# ATtiny13A register map
Vendor: Atmel; File version: 1.0
CPU: other r0p0, little endian, no MPU, no FPU, 4 interrupt priority bits
Registers are 8-bit, read-write, reset 0x0 unless marked. A register's access mark holds for its fields unless they carry their own. Offsets are from the block's base; lines under a group give offsets from that group; [hi:lo] are bit positions; {n}, {i} and the like mark numbered series; 'fields as' and 'values as' point back to an identical list; <NAME> marks a mode.

## Memory map
0x00000000 FUSE size 0x2 — Fuses
0x00000000 LOCKBIT size 0x1 — Lockbits
0x00000023 AC blocks up to offset 0x12 — Analog Comparator
0x00000023 ADC blocks up to offset 0x12 — Analog-to-Digital Converter
0x00000035 EXINT blocks up to offset 0x27 — External Interrupts
0x00000036 PORTB size 0x3 — I/O Port
0x0000003C EEPROM size 0x3
0x00000041 WDT size 0x1 — Watchdog Timer
0x00000045 CPU blocks up to offset 0x19 — CPU Registers
0x00000048 TC0 blocks up to offset 0x12 — Timer/Counter, 8-bit

## Interrupts
0 RESET (CPU) — External Reset, Power-on Reset and Watchdog Reset
1 INT0 (CPU) — External Interrupt 0
2 PCINT0 (CPU) — External Interrupt Request 0
3 TIM0_OVF (CPU) — Timer/Counter0 Overflow
4 EE_RDY (CPU) — EEPROM Ready
5 ANA_COMP (CPU) — Analog Comparator
6 TIM0_COMPA (CPU) — Timer/Counter Compare Match A
7 TIM0_COMPB (CPU) — Timer/Counter Compare Match B
8 WDT (CPU) — Watchdog Time-out
9 ADC (CPU) — ADC Conversion Complete

## AC — Analog Comparator
Base 0x00000023
0x00 ADCSRB — ADC Control and Status Register B
  [6] ACME — Analog Comparator Multiplexer Enable
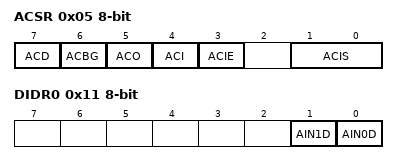
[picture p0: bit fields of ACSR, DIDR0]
0x05 ACSR — Analog Comparator Control And Status Register
  [7] ACD — Analog Comparator Disable
  [6] ACBG — Analog Comparator Bandgap Select
  [5] ACO — Analog Compare Output
  [4] ACI — Analog Comparator Interrupt Flag
  [3] ACIE — Analog Comparator Interrupt Enable
  [1:0] ACIS — Analog Comparator Interrupt Mode Select bits
    0=INTERRUPT_ON_TOGGLE; 2=INTERRUPT_ON_FALLING_EDGE; 3=INTERRUPT_ON_RISING_EDGE
0x11 DIDR0
  [1] AIN1D — AIN1 Digital Input Disable
  [0] AIN0D — AIN0 Digital Input Disable

## ADC — Analog-to-Digital Converter
Base 0x00000023
0x00 ADCSRB — ADC Control and Status Register B
  [2:0] ADTS — ADC Auto Trigger Sources
    0=FREE_RUNNING_MODE; 1=ANALOG_COMPARATOR; 2=EXTERNAL_INTERRUPT_REQUEST_0; 3=TIMER_COUNTER0_COMPARE_MATCH_A; 4=TIMER_COUNTER0_OVERFLOW; 5=TIMER_COUNTER1_COMPARE_MATCH_B; 6=TIMER_COUNTER1_OVERFLOW; 7=TIMER_COUNTER1_CAPTURE_EVENT
0x01 ADC 16-bit (reset mask 0xFF) — ADC Data Register Bytes
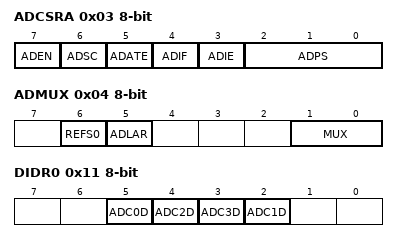
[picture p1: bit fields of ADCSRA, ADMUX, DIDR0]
0x03 ADCSRA — The ADC Control and Status register
  [7] ADEN — ADC Enable
  [6] ADSC — ADC Start Conversion
  [5] ADATE — ADC Auto Trigger Enable
  [4] ADIF — ADC Interrupt Flag
  [3] ADIE — ADC Interrupt Enable
  [2:0] ADPS — ADC Prescaler Select Bits
    1=2; 2=4; 3=8; 4=16; 5=32; 6=64; 7=128
0x04 ADMUX — The ADC multiplexer Selection Register
  [6] REFS0 — Reference Selection Bit 0
  [5] ADLAR — Left Adjust Result
  [1:0] MUX — Analog Channel and Gain Selection Bits
0x11 DIDR0 — Digital Input Disable Register 0
  [5] ADC0D — ADC0 Digital input Disable
  [4] ADC2D — ADC2 Digital input Disable
  [3] ADC3D — ADC3 Digital input Disable
  [2] ADC1D — ADC2 Digital input Disable

## CPU — CPU Registers
Base 0x00000045
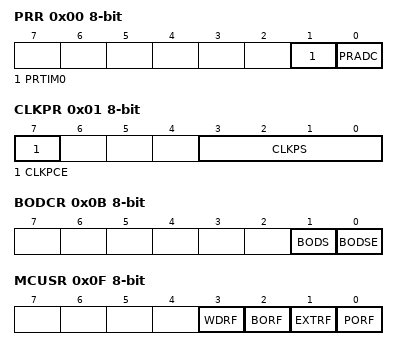
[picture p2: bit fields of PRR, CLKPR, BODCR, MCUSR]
0x00 PRR — Power Reduction Register
  [1] PRTIM0 — Power Reduction Timer/Counter0
  [0] PRADC — Power Reduction ADC
0x01 CLKPR — Clock Prescale Register
  [7] CLKPCE — Clock Prescaler Change Enable
  [3:0] CLKPS — Clock Prescaler Select Bits
    0=1; 1=2; 2=4; 3=8; 4=16; 5=32; 6=64; 7=128; 8=256
0x09 DWDR — Debug Wire Data Register
0x0B BODCR — BOD Control Register
  [1] BODS — BOD Power-Down in Power-Down Sleep
  [0] BODSE — BOD Power-Down Sleep Enable
0x0C OSCCAL — Oscillator Calibration Register
  [7:0] OSCCAL — Oscillator Calibration
0x0F MCUSR — MCU Status register
  [3] WDRF — Watchdog Reset Flag
  [2] BORF — Brown-out Reset Flag
  [1] EXTRF — External Reset Flag
  [0] PORF — Power-On Reset Flag
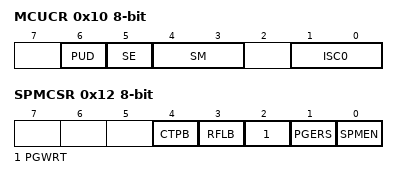
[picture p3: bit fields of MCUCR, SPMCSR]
0x10 MCUCR — MCU Control Register
  [6] PUD — Pull-up Disable
  [5] SE — Sleep Enable
  [4:3] SM — Sleep Mode Select Bits
    0=IDLE; 1=ADC (ADC Noise Reduction (If Available)); 2=PDOWN (Power Down)
  [1:0] ISC0 — Interrupt Sense Control 0 bits
    0=LOW_LEVEL_OF_INTX; 1=ANY_LOGICAL_CHANGE_IN_INTX; 2=FALLING_EDGE_OF_INTX; 3=RISING_EDGE_OF_INTX
0x12 SPMCSR — Store Program Memory Control and Status Register
  [4] CTPB — Clear Temporary Page Buffer
  [3] RFLB — Read Fuse and Lock Bits
  [2] PGWRT — Page Write
  [1] PGERS — Page Erase
  [0] SPMEN — Store program Memory Enable
0x18 SPL — Stack Pointer Low Byte
